# SF32LB58x register map
File version: 1.0
CPU: CM33 r0p1, little endian, MPU, FPU, 3 interrupt priority bits
Registers are 32-bit, read-write, reset 0x0 unless marked. A register's access mark holds for its fields unless they carry their own. Offsets are from the block's base; [hi:lo] are bit positions; {n}, {i} and the like mark numbered series.

## HPSYS_AON
Base 0x40040000
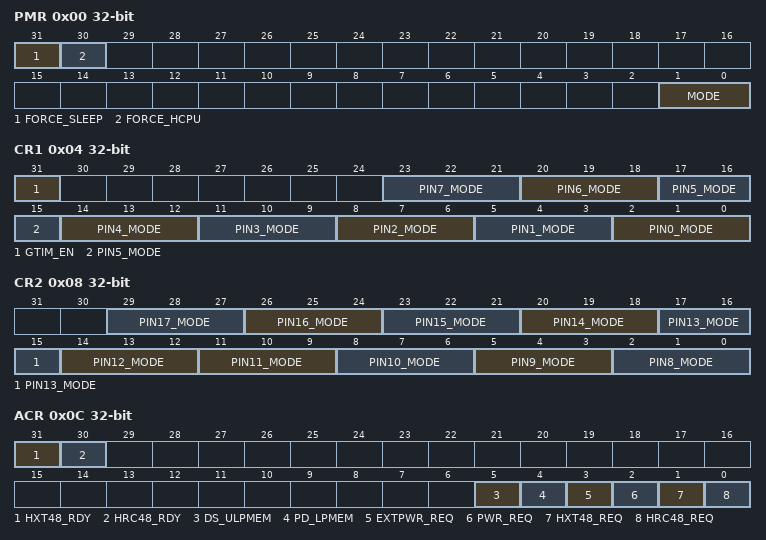
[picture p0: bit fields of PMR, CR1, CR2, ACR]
0x00 PMR — Power Mode Register
  [31] FORCE_SLEEP — Force to enter low power mode (for debug only)
  [30] FORCE_HCPU — for debug only
  [1:0] MODE — Power Mode: 2'h0 - active/idle; 2'h1 - light sleep; 2'h2 - deep sleep; 2'h3 - standby
0x04 CR1 — Control Register 1
  [31] GTIM_EN — Enable global timer
  [23:21] PIN7_MODE — mode for wakeup PIN7 (PA65)
  [20:18] PIN6_MODE — mode for wakeup PIN6 (PA64)
  [3n+2:3n] PIN{n}_MODE (n=1..5) — mode for wakeup PIN{n} (PB{n+54})
  [2:0] PIN0_MODE — mode for wakeup PIN0 (PB54) 0 - high level, 1 - low level, 2 - pos edge, 3 - neg edge, 4/5/6/7: pos or neg edge
0x08 CR2 — Control Register 2
  [3n-22:3n-24] PIN{n}_MODE (n=12..17) — mode for wakeup PIN{n} (PBR{n-12})
  [11:9] PIN11_MODE — mode for wakeup PIN11 (PA69)
  [8:6] PIN10_MODE — mode for wakeup PIN10 (PA68)
  [5:3] PIN9_MODE — mode for wakeup PIN9 (PA67)
  [2:0] PIN8_MODE — mode for wakeup PIN8 (PA66) 0 - high level, 1 - low level, 2 - pos edge, 3 - neg edge, 4/5/6/7: pos or neg edge
0x0C ACR — Active Mode Control register
  [31] HXT48_RDY — Indicate hxt48 is ready
  [30] HRC48_RDY — Indicate hrc48 is ready
  [5] DS_ULPMEM — for debug only
  [4] PD_LPMEM — for debug only
  [3] EXTPWR_REQ — Request power for LPSYS during Active mode
  [2] PWR_REQ — Request power for HPSYS during Active mode
  [1] HXT48_REQ — Request hxt48 in active mode
  [0] HRC48_REQ — Request hrc48 in active mode
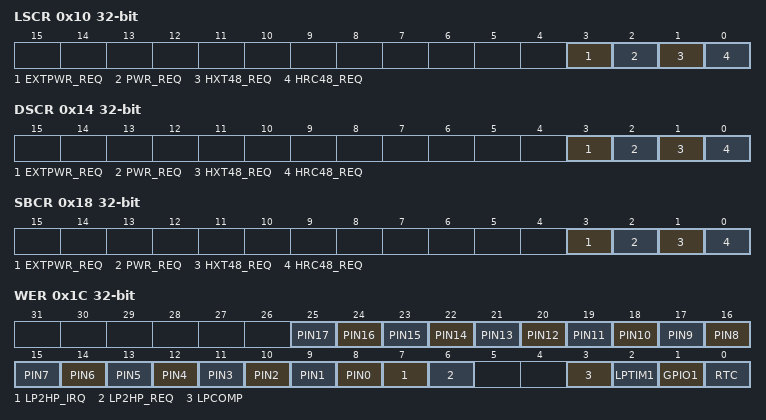
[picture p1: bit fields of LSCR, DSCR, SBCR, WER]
0x10 LSCR — Light Sleep Ctrl Register
  [3] EXTPWR_REQ — Request power for LPSYS during Light Sleep mode
  [2] PWR_REQ — Request power for HPSYS during Light Sleep mode
  [1] HXT48_REQ — Request hxt48 in Light Sleep mode
  [0] HRC48_REQ — Request hrc48 in Light Sleep mode
0x14 DSCR — Deep Sleep Ctrl Register
  [3] EXTPWR_REQ — Request power for LPSYS during Deep Sleep mode
  [2] PWR_REQ — Request power for HPSYS during Deep Sleep mode
  [1] HXT48_REQ — Request hxt48 in Deep Sleep mode
  [0] HRC48_REQ — Request hrc48 in Deep Sleep mode
0x18 SBCR — Standby Mode Ctrl Register
  [3] EXTPWR_REQ — Request power for LPSYS during Standby mode
  [2] PWR_REQ — Request power for HPSYS during Standby mode
  [1] HXT48_REQ — Request hxt48 in Standby mode
  [0] HRC48_REQ — Request hrc48 in Standby mode
0x1C WER — Wakeup Enable register
  [n+8] PIN{n} (n=12..17) — Set 1 to enable PBR{n-12} as wakeup source
  [n+8] PIN{n} (n=6..11) — Set 1 to enable PA{n+58} as wakeup source
  [n+8] PIN{n} (n=0..5) — Set 1 to enable PB{n+54} as wakeup source
  [7] LP2HP_IRQ — Set 1 to enable MAILBOX2 as wakeup source
  [6] LP2HP_REQ — Set 1 to enable LPSYS request as wakeup source
  [3] LPCOMP — Set 1 to enable LPCOMP as wakeup source
  [2] LPTIM1 — Set 1 to enable LPTIM1 as wakeup source
  [1] GPIO1 — Set 1 to enable IO(PA) as wakeup source
  [0] RTC — Set 1 to enable RTC as wakeup source
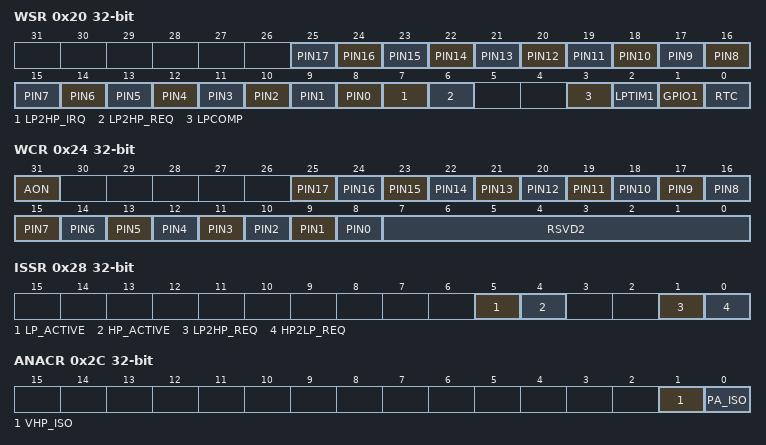
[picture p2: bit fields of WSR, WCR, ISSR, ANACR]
0x20 WSR — Wakeup Status register
  [n+8] PIN{n} (n=12..17) — Indicates the wakeup status from PBR{n-12} request. Note: the status is masked by WER
  [n+8] PIN{n} (n=6..11) — Indicates the wakeup status from PA{n+58} request. Note: the status is masked by WER
  [n+8] PIN{n} (n=0..5) — Indicates the wakeup status from PB{n+54} request. Note: the status is masked by WER
  [7] LP2HP_IRQ — Indicates the wakeup status from MAILBOX2. Note: the status is masked by WER
  [6] LP2HP_REQ — Indicates the wakeup status from LPSYS request. Note: the status is masked by WER
  [3] LPCOMP — Indicates the wakeup status from LPCOMP. Note: the status is masked by WER
  [2] LPTIM1 — Indicates the wakeup status from LPTIM1. Note: the status is masked by WER
  [1] GPIO1 — Indicates the wakeup status from IO(PA). Note: the status is masked by WER
  [0] RTC — Indicates the wakeup status from RTC. Note: the status is masked by WER
0x24 WCR — Wakeup Clear register
  [31] AON — Write 1 to clear the AON wakeup IRQ status
  [n+8] PIN{n} (n=12..17) — Write 1 to clear PBR{n-12} wakeup source. Only valid if PIN wakeup is configured as edge trigger
  [n+8] PIN{n} (n=6..11) — Write 1 to clear PA{n+58} wakeup source. Only valid if PIN wakeup is configured as edge trigger
  [n+8] PIN{n} (n=0..5) — Write 1 to clear PB{n+54} wakeup source. Only valid if PIN wakeup is configured as edge trigger
  [7:0] RSVD2 — Note: for LPTIM and RTC, clear the wakeup status directly in the orignal module
0x28 ISSR — Inter System Wakeup Register
  [5] LP_ACTIVE — read 1 indicates LPSYS is active
  [4] HP_ACTIVE — write 1 to indicates HPSYS is active
  [1] LP2HP_REQ — indicate LPSYS request exists
  [0] HP2LP_REQ — write 1 to request LPSYS to stay in active mode
0x2C ANACR — Analog Control Register
  [1] VHP_ISO — Set 1 to force off all HPSYS related analog modules
  [0] PA_ISO — Set 1 to force IO(PA) into retention mode
0x30 GTIMR — Global Timer Register
  [31:0] CNT — Global timer value
0x34 RESERVE0 — Reserved Register 0
  [31:0] DATA — for debug only
0x38 RESERVE1 — Reserved Register 1
  [31:0] DATA — for debug only
